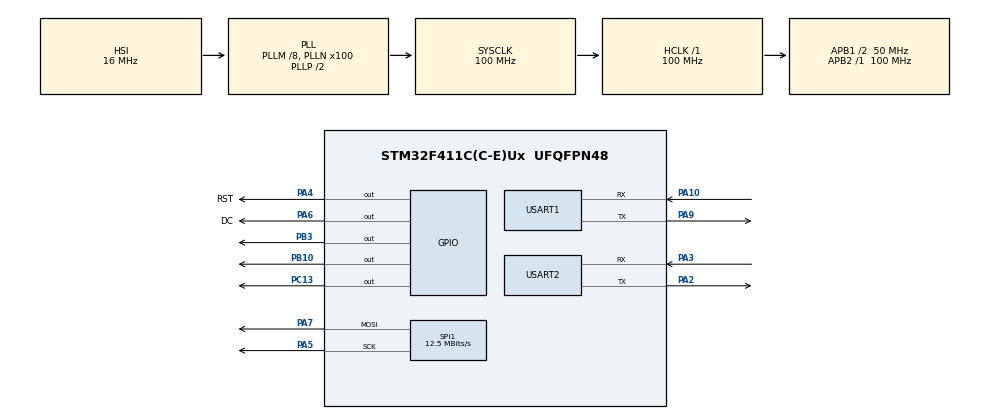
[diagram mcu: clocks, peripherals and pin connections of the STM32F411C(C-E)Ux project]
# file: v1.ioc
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Dma.Request0=SPI1_TX
Dma.SPI1_TX.0.Direction=DMA_MEMORY_TO_PERIPH
Dma.SPI1_TX.0.FIFOMode=DMA_FIFOMODE_DISABLE
Dma.SPI1_TX.0.Instance=DMA2_Stream2
Dma.SPI1_TX.0.MemDataAlignment=DMA_MDATAALIGN_BYTE
Dma.SPI1_TX.0.MemInc=DMA_MINC_ENABLE
Dma.SPI1_TX.0.Mode=DMA_NORMAL
Dma.SPI1_TX.0.PeriphDataAlignment=DMA_PDATAALIGN_BYTE
Dma.SPI1_TX.0.PeriphInc=DMA_PINC_DISABLE
Dma.SPI1_TX.0.Priority=DMA_PRIORITY_LOW
Mcu.Family=STM32F4
Mcu.Name=STM32F411C(C-E)Ux
Mcu.Package=UFQFPN48
NVIC.DMA2_Stream2_IRQn=true\:0\:0\:false\:false\:true\:false\:true\:true
NVIC.PriorityGroup=NVIC_PRIORITYGROUP_4
NVIC.TIM1_BRK_TIM9_IRQn=true\:0\:0\:false\:false\:true\:true\:true\:true
NVIC.USART1_IRQn=true\:0\:0\:false\:false\:true\:true\:true\:true
NVIC.USART2_IRQn=true\:0\:0\:false\:false\:true\:true\:true\:true
PA10.Mode=Asynchronous
PA10.Signal=USART1_RX
PA13.Mode=Serial_Wire
PA13.Signal=SYS_JTMS-SWDIO
PA14.Mode=Serial_Wire
PA14.Signal=SYS_JTCK-SWCLK
PA2.Mode=Asynchronous
PA2.Signal=USART2_TX
PA3.Mode=Asynchronous
PA3.Signal=USART2_RX
PA4.GPIO_Label=RST
PA4.Signal=GPIO_Output
PA5.Mode=TX_Only_Simplex_Unidirect_Master
PA5.Signal=SPI1_SCK
PA6.GPIO_Label=DC
PA6.Signal=GPIO_Output
PA7.Mode=TX_Only_Simplex_Unidirect_Master
PA7.Signal=SPI1_MOSI
PA9.Mode=Asynchronous
PA9.Signal=USART1_TX
PB10.GPIO_ModeDefaultOutputPP=GPIO_MODE_OUTPUT_OD
PB10.GPIO_PuPd=GPIO_PULLUP
PB10.GPIO_Speed=GPIO_SPEED_FREQ_HIGH
PB10.PinState=GPIO_PIN_SET
PB10.Signal=GPIO_Output
PB3.GPIO_ModeDefaultOutputPP=GPIO_MODE_OUTPUT_OD
PB3.GPIO_PuPd=GPIO_PULLUP
PB3.GPIO_Speed=GPIO_SPEED_FREQ_HIGH
PB3.PinState=GPIO_PIN_SET
PB3.Signal=GPIO_Output
PC13-ANTI_TAMP.Signal=GPIO_Output
PC14-OSC32_IN.Mode=LSE-External-Oscillator
PC14-OSC32_IN.Signal=RCC_OSC32_IN
PC15-OSC32_OUT.Mode=LSE-External-Oscillator
PC15-OSC32_OUT.Signal=RCC_OSC32_OUT
PH0\ -\ OSC_IN.Mode=HSE-External-Oscillator
PH0\ -\ OSC_IN.Signal=RCC_OSC_IN
PH1\ -\ OSC_OUT.Mode=HSE-External-Oscillator
PH1\ -\ OSC_OUT.Signal=RCC_OSC_OUT
ProjectManager.HeapSize=0x200
ProjectManager.StackSize=0x400
ProjectManager.TargetToolchain=STM32CubeIDE
RCC.48MHZClocksFreq_Value=50000000
RCC.AHBFreq_Value=100000000
RCC.APB1CLKDivider=RCC_HCLK_DIV2
RCC.APB1Freq_Value=50000000
RCC.APB1TimFreq_Value=100000000
RCC.APB2Freq_Value=100000000
RCC.APB2TimFreq_Value=100000000
RCC.CortexFreq_Value=100000000
RCC.HCLKFreq_Value=100000000
RCC.HSE_VALUE=25000000
RCC.HSI_VALUE=16000000
RCC.PLLM=8
RCC.PLLN=100
RCC.SYSCLKFreq_VALUE=100000000
RCC.SYSCLKSource=RCC_SYSCLKSOURCE_PLLCLK
RCC.VCOOutputFreq_Value=200000000
SPI1.BaudRatePrescaler=SPI_BAUDRATEPRESCALER_8
SPI1.CalculateBaudRate=12.5 MBits/s
SPI1.Direction=SPI_DIRECTION_2LINES
SPI1.Mode=SPI_MODE_MASTER
SPI1.VirtualType=VM_MASTER
TIM9.AutoReloadPreload=TIM_AUTORELOAD_PRELOAD_ENABLE
TIM9.Period=999
TIM9.Prescaler=99
USART1.VirtualMode=VM_ASYNC
USART2.VirtualMode=VM_ASYNC
VP_TIM9_VS_ClockSourceINT.Mode=Internal
board=custom

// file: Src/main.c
/* USER CODE BEGIN Header */
/**
  ******************************************************************************
  * @file           : main.c
  * @brief          : Main program body
  ******************************************************************************
  * @attention
  *
  * Copyright (c) 2023 STMicroelectronics.
  * All rights reserved.
  *
  * This software is licensed under terms that can be found in the LICENSE file
  * in the root directory of this software component.
  * If no LICENSE file comes with this software, it is provided AS-IS.
  *
  ******************************************************************************
  */
/* USER CODE END Header */
#include "main.h"
#include "dma.h"
#include "spi.h"
#include "tim.h"
#include "usart.h"
#include "gpio.h"

/* USER CODE BEGIN Includes */
#include "stdio.h"
#include "printf.h"
//#include "pca9685.h"
//#include "iic_check.h"
#include "oled_spi_hd.h"
#include "string.h"
#include "pca9685_sim.h"
/* USER CODE END Includes */

/* USER CODE BEGIN PV */
uint8_t oled_buff[21];
/* USER CODE END PV */

void SystemClock_Config(void);

int main(void)
{

  /* MCU Configuration--------------------------------------------------------*/

  /* Reset of all peripherals, Initializes the Flash interface and the Systick. */
  HAL_Init();

  /* Configure the system clock */
  SystemClock_Config();

  /* Initialize all configured peripherals */
  MX_GPIO_Init();
  MX_DMA_Init();
  MX_SPI1_Init();
  MX_TIM9_Init();
  MX_USART1_UART_Init();
  MX_USART2_UART_Init();
  /* USER CODE BEGIN 2 */

  pca9685_Init();

  HAL_TIM_Base_Start_IT(&htim9);
  OLED_Init();

//  if(iic_check(0x80))
//  {
//    sprintf((char*)oled_buff,"Ox80 Device: NO!   ");
//    OLED_ShowString(0,2,(uint8_t*)oled_buff);
//    memset(oled_buff,0, strlen((const char*)oled_buff));
//  }
//  else
//  {
//    sprintf((char*)oled_buff,"Ox80 Device: OK!   ");
//    OLED_ShowString(0,2,(uint8_t*)oled_buff);
//    memset(oled_buff,0, strlen((const char*)oled_buff));
//  }
//  if(iic_check(0x82))
//  {
//    sprintf((char*)oled_buff,"Ox82 Device: NO!   ");
//    OLED_ShowString(0,4,(uint8_t*)oled_buff);
//    memset(oled_buff,0, strlen((const char*)oled_buff));
//  }
//  else
//  {
//    sprintf((char*)oled_buff,"Ox82 Device: OK!   ");
//    OLED_ShowString(0,4,(uint8_t*)oled_buff);
//    memset(oled_buff,0, strlen((const char*)oled_buff));
//  }
//
//  if(iic_check(0x68))
//  {
//    sprintf((char*)oled_buff,"Ox68 Device: NO!");
//    OLED_ShowString(0,6,(uint8_t*)oled_buff);
//    memset(oled_buff,0, strlen((const char*)oled_buff));
//  }
//  else
//  {
//    sprintf((char*)oled_buff,"Ox68 Device: OK!");
//    OLED_ShowString(0,6,(uint8_t*)oled_buff);
//    memset(oled_buff,0, strlen((const char*)oled_buff));
//  }

  set_ServoAngle(0,30);
  set_ServoAngle(1,60);
  set_ServoAngle(2,130);
  set_ServoAngle(3,170);

  /* USER CODE END 2 */

  /* Infinite loop */
  while (1)
  {

  }
}

void SystemClock_Config(void)
{
  RCC_OscInitTypeDef RCC_OscInitStruct = {0};
  RCC_ClkInitTypeDef RCC_ClkInitStruct = {0};

  /** Configure the main internal regulator output voltage
  */
  __HAL_RCC_PWR_CLK_ENABLE();
  __HAL_PWR_VOLTAGESCALING_CONFIG(PWR_REGULATOR_VOLTAGE_SCALE1);

  /** Initializes the RCC Oscillators according to the specified parameters
  * in the RCC_OscInitTypeDef structure.
  */
  RCC_OscInitStruct.OscillatorType = RCC_OSCILLATORTYPE_HSI;
  RCC_OscInitStruct.HSIState = RCC_HSI_ON;
  RCC_OscInitStruct.HSICalibrationValue = RCC_HSICALIBRATION_DEFAULT;
  RCC_OscInitStruct.PLL.PLLState = RCC_PLL_ON;
  RCC_OscInitStruct.PLL.PLLSource = RCC_PLLSOURCE_HSI;
  RCC_OscInitStruct.PLL.PLLM = 8;
  RCC_OscInitStruct.PLL.PLLN = 100;
  RCC_OscInitStruct.PLL.PLLP = RCC_PLLP_DIV2;
  RCC_OscInitStruct.PLL.PLLQ = 4;
  if (HAL_RCC_OscConfig(&RCC_OscInitStruct) != HAL_OK)
  {
    Error_Handler();
  }

  /** Initializes the CPU, AHB and APB buses clocks
  */
  RCC_ClkInitStruct.ClockType = RCC_CLOCKTYPE_HCLK|RCC_CLOCKTYPE_SYSCLK
                              |RCC_CLOCKTYPE_PCLK1|RCC_CLOCKTYPE_PCLK2;
  RCC_ClkInitStruct.SYSCLKSource = RCC_SYSCLKSOURCE_PLLCLK;
  RCC_ClkInitStruct.AHBCLKDivider = RCC_SYSCLK_DIV1;
  RCC_ClkInitStruct.APB1CLKDivider = RCC_HCLK_DIV2;
  RCC_ClkInitStruct.APB2CLKDivider = RCC_HCLK_DIV1;

  if (HAL_RCC_ClockConfig(&RCC_ClkInitStruct, FLASH_LATENCY_3) != HAL_OK)
  {
    Error_Handler();
  }
}

void Error_Handler(void)
{
  __disable_irq();
  while (1)
  {
  }
}
